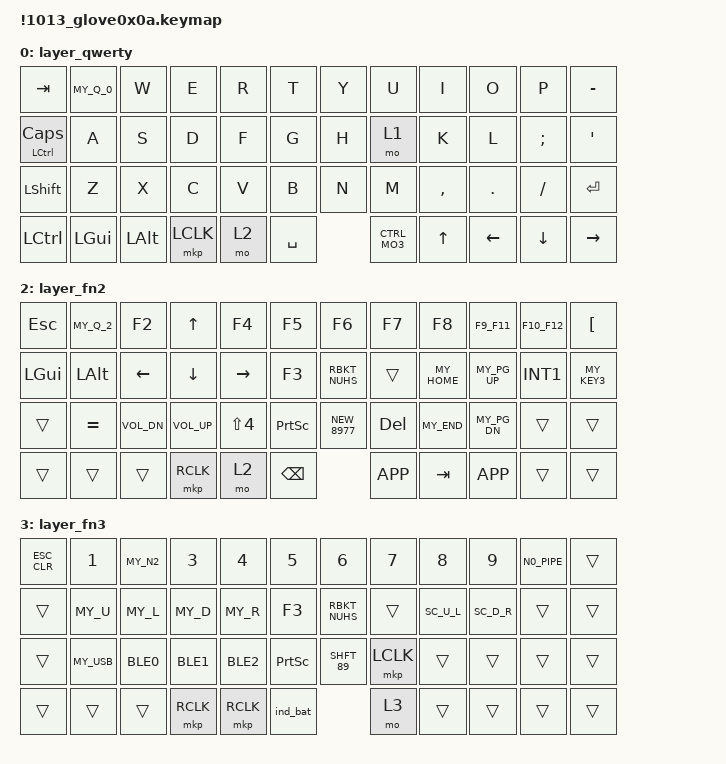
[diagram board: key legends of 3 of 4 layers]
#include <behaviors.dtsi>
#include <dt-bindings/zmk/keys.h>
#include <dt-bindings/zmk/bt.h>
#include <dt-bindings/zmk/outputs.h>
#include <dt-bindings/zmk/rgb.h>
#include <behaviors/rgbled_widget.dtsi>

//define
//ロータリーエンコーダ：マウスのスクロール量
#define ZMK_POINTING_DEFAULT_MOVE_VAL 1500
#define ZMK_POINTING_DEFAULT_SCRL_VAL 60
#include <dt-bindings/zmk/pointing.h>
#include <dt-bindings/input/input-event-codes.h>

#define TAP_MS 200
#define HOLD_MS 200
#define PIPE_ LS(INT3)

#define _USB OUT_USB
#define _BLE OUT_BLE
#define _BT  BT_SEL

#define SC_U SCRL_UP
#define SC_D SCRL_DOWN
#define SC_L SCRL_LEFT
#define SC_R SCRL_RIGHT

#define DUMM MOVE_Y(-1)
#define LO_U MOVE_Y(-1000)
#define LO_D MOVE_Y(1000)
#define LO_L MOVE_X(-1000)
#define LO_R MOVE_X(1000)
#define HI_U MOVE_Y(-200)
#define HI_D MOVE_Y(200)
#define HI_L MOVE_X(-200)
#define HI_R MOVE_X(200)

//2026.03.17 #980 Ctrl + TAB or Q(Shift TAB) / Alt + Q(TAB) or W(Shit+TAB)
//2026.03.16 #979 Layer1のGUI押下中のHOME/END/PGUP/PGDNをLC()送付&GUIリリース前にESC送信に修正(mod-morph)。
//2026.03.16 #968 没。めっちゃムズイ。バッテリー監視も無効になる。:WS2812(LED)の有効化/AZ1UBALLから並列で電源供給
//2026.03.14 #921 ダブルタップは250ms(ちょっと余裕がある)
//2026.03.14 #919 Q、TABへ。mod-morphの修飾キーマスク削除。
//2026.03.14 #919 hold-tapで他キー割込み時はhold->tap扱いへ
//2026.03.14 #907 fn2度押し->Ctrlへ。
//2026.03.13 #881 tap-danceの自動リリース削除、押しっぱなしでホールド/即リリースは後追い。
//2026.03.12 #873 物理配置を再調整。D1が不調。
//2026.03.03 #860   レイヤー3で左クリック
//2026.03.02 #853 i2c/jiggler/加速度/47キー/マウス基本を低速へ//2026.03.02 #852   47キーバージョンへ戻し。左下キー削減のリハビリから。
//2026.03.01 #847   Ctrlキーを再配置、BLE機能関連のキー再配置
//2026.03.01 #843 デバッグ:AZ1UBALL:加速度上限制御。//2026.03.01 #842 デバッグ:AZ1UBALL:前回移動量のクリアを明記。//2026.03.01 #841 デバッグ:AZ1UBALL:前回移動量の保存条件を変更。//2026.03.01 #838 デバッグ:AZ1UBALL:cos/sinの符号不良。//2026.03.01 #837 デバッグ:AZ1UBALL:方向検出不良(if右else左else下else上->if右else左 if下else上)//2026.02.28 #834 デバッグ:AZ1UBALL:加速度不良。
//2026.02.28 #832 左Fnのレイヤー上段にFXを集約。整理。
//2026.02.28 #828 AZ1UBALLのカスタマイズ。移動量,角度,加速度。
//2026.02.23 #800 I2Cでマウス、ジグラーはレイヤー1へ。Fn2で速度追加、Fn3でカーソル。レイヤー1は未点灯。
//2026.02.23 #798 I2Cでマウス、Fn1で速度追加、Fn2でカーソル、ジグラーはレイヤー3へ。
//2026.02.23 #765 I2CのSDA(D4)、SCL(D5)を明示的に指定。
//2026.02.23 #764 zmkバージョンアップにより、rgbledをローカルzmkへ統合。OK
//2026.02.23 #764 ZIGGLER ON/OFFのため、JキーをF13へ。(物理スイッチあり)
&mt {
    tapping-term-ms = <HOLD_MS>;  //hold-tap / caps -> Ctrl
};
/ {
//★macro---------------------------------------------------
    macros {
        MY_USB: MY_USB {
            compatible = "zmk,behavior-macro";
            #binding-cells = <0>;
            bindings
                = <&macro_tap &out OUT_USB>
                , <&macro_tap &bt BT_SEL 5 >;
        };
        BLE0: BLE0 {
            compatible = "zmk,behavior-macro";
            #binding-cells = <0>;
            bindings
                = <&macro_tap &out OUT_BLE>
                , <&macro_tap &bt BT_SEL 0 >;
        };
        BLE1: BLE1 {
            compatible = "zmk,behavior-macro";
            #binding-cells = <0>;
            bindings
                = <&macro_tap &out OUT_BLE>
                , <&macro_tap &bt BT_SEL 1 >;
        };
        BLE2: BLE2 {
            compatible = "zmk,behavior-macro";
            #binding-cells = <0>;
            bindings
                = <&macro_tap &out OUT_BLE>
                , <&macro_tap &bt BT_SEL 2 >;
        };
        N_RBKT_NUHS: N_RBKT_NUHS {
            compatible = "zmk,behavior-macro";
            #binding-cells = <0>;
            bindings
                = <&kp RBKT &kp NUHS &kp LEFT>;
        };
        S_RBKT_NUHS: S_RBKT_NUHS {
            compatible = "zmk,behavior-macro";
            #binding-cells = <0>;
            bindings
                = <&kp LS(RBKT) &kp LS(NUHS) &kp LEFT>;
        };
        SHFT_89: SHFT_89 {
            compatible = "zmk,behavior-macro";
            #binding-cells = <0>;
            bindings
                = <&kp LS(N8) &kp LS(N9) &kp LEFT>;
        };
        SHFT_77: SHFT_77 {
            compatible = "zmk,behavior-macro";
            #binding-cells = <0>;
            bindings
                = <&kp LS(N7) &kp LS(N7) &kp LEFT>;
        };
        SHFT_22: SHFT_22 {
            compatible = "zmk,behavior-macro";
            #binding-cells = <0>;
            bindings
                = <&kp LS(N2) &kp LS(N2) &kp LEFT>;
        };
    };
////behaviors
    behaviors {
//★mod-morph-----------------------------------------------
        //ボリューム操作(Win->UNIX)
        VOL_UP: VOL_UP {
            compatible = "zmk,behavior-mod-morph";
            #binding-cells = <0>;
            bindings = <&kp C_VOL_UP>, <&kp K_VOL_UP>;
            mods = <MOD_LSFT>;
        };
        VOL_DN: VOL_DN {
            compatible = "zmk,behavior-mod-morph";
            #binding-cells = <0>;
            bindings = <&kp C_VOL_DN>, <&kp K_VOL_DN>;
            mods = <MOD_LSFT>;
        };
        //0.ESC
        ESC_CLR: ESC_CLR {  /*ESC_CLR*/
            compatible = "zmk,behavior-mod-morph";
            #binding-cells = <0>;
            bindings = <&kp ESC>, <&bt BT_CLR >;
            mods = <MOD_LSFT>;
        };
        //1.Q
        MY_Q_0: MY_Q_0 {  //Alt or Ctrl
            compatible = "zmk,behavior-mod-morph";
            #binding-cells = <0>;
            bindings = <&kp Q>, <&kp LS(TAB)>;
            mods = <(MOD_LALT|MOD_LCTL)>;
        };
        QUIT_F1: QUIT_F1 {  /* QUIT_F1 */
            compatible = "zmk,behavior-mod-morph";
            #binding-cells = <0>;
            bindings = <&kp LA(F4)>, <&kp F1>;
            mods = <MOD_LSFT>;
        };
        MY_Q_2: MY_Q_2 {    //Alt
            compatible = "zmk,behavior-mod-morph";
            #binding-cells = <0>;
            bindings = <&QUIT_F1>, <&kp TAB >;
            mods = <(MOD_LALT|MOD_LCTL)>;
        };
        //9.O
        F9_F11: F9_F11 {    /* F9_F11 */
            compatible = "zmk,behavior-mod-morph";
            #binding-cells = <0>;
            bindings = <&kp F9>, <&kp F11>;
            mods = <MOD_LSFT>;
        };
        //10.P
        F10_F12: F10_F12 {  /* F10_F12 */
            compatible = "zmk,behavior-mod-morph";
            #binding-cells = <0>;
            bindings = <&kp F10>, <&kp F12>;
            mods = <MOD_LSFT>;
        };
        N0_PIPE: N0_PIPE {  /* N0 & pipe */
            compatible = "zmk,behavior-mod-morph";
            #binding-cells = <0>;
            bindings = <&kp N0>, <&kp PIPE_>;
            mods = <MOD_LSFT>;
        };
        //23.:
        MY_KEY3: MY_KEY3 {  /*【~】【*】 */
            compatible = "zmk,behavior-mod-morph";
            #binding-cells = <0>;
            bindings = <&kp LS(EQUAL)>, <&kp LS(SQT)>;
            mods = <MOD_LSFT>;
        };
        //NEW_2:
        MY_N2: MY_N2 {
            compatible = "zmk,behavior-mod-morph";
            #binding-cells = <0>;
            bindings = <&kp N2>, <&SHFT_22>;
            mods = <MOD_LSFT>;
        };
        //NEW_8977:
        RBKT_NUHS: RBKT_NUHS {
            compatible = "zmk,behavior-mod-morph";
            #binding-cells = <0>;
            bindings = <&N_RBKT_NUHS>, <&S_RBKT_NUHS>;
            mods = <MOD_LSFT>;
        };
        //NEW_8977:
        NEW_8977: NEW_8977 {
            compatible = "zmk,behavior-mod-morph";
            #binding-cells = <0>;
            bindings = <&SHFT_89>, <&SHFT_77>;
            mods = <MOD_LSFT>;
        };
//////////十字キー
        MY_R: MY_R{
            compatible = "zmk,behavior-mod-morph";
            #binding-cells = <0>;
            bindings = <&mmv LO_R>, <&mmv HI_R>;
            mods = <MOD_LSFT>;
        };
        MY_U: MY_U{
            compatible = "zmk,behavior-mod-morph";
            #binding-cells = <0>;
            bindings = <&mmv LO_U>, <&mmv HI_U>;
            mods = <MOD_LSFT>;
        };
        MY_L: MY_L{
            compatible = "zmk,behavior-mod-morph";
            #binding-cells = <0>;
            bindings = <&mmv LO_L>, <&mmv HI_L>;
            mods = <MOD_LSFT>;
        };
        MY_D: MY_D{
            compatible = "zmk,behavior-mod-morph";
            #binding-cells = <0>;
            bindings = <&mmv LO_D>, <&mmv HI_D>;
            mods = <MOD_LSFT>;
        };
//////////スクロール
        SC_U_L: SC_U_L{
            compatible = "zmk,behavior-mod-morph";
            #binding-cells = <0>;
            bindings = <&msc SC_U>, <&msc SC_L>;
            mods = <MOD_LSFT>;
        };
        SC_D_R: SC_D_R{
            compatible = "zmk,behavior-mod-morph";
            #binding-cells = <0>;
            bindings = <&msc SC_D>, <&msc SC_R>;
            mods = <MOD_LSFT>;
        };
//////////ページ操作
        MY_HOME: MY_HOME {
            compatible = "zmk,behavior-mod-morph";
            #binding-cells = <0>;
            bindings = <&kp HOME>, <&kp LC(HOME) >;
            mods = <MOD_LGUI>;
        };
        MY_END: MY_END {
            compatible = "zmk,behavior-mod-morph";
            #binding-cells = <0>;
            bindings = <&kp END>, <&kp LC(END) >;
            mods = <MOD_LGUI>;
        };
        MY_PG_UP: MY_PG_UP {
            compatible = "zmk,behavior-mod-morph";
            #binding-cells = <0>;
            bindings = <&kp PG_UP>, <&kp LC(PG_UP) >;
            mods = <MOD_LGUI>;
        };
        MY_PG_DN: MY_PG_DN {
            compatible = "zmk,behavior-mod-morph";
            #binding-cells = <0>;
            bindings = <&kp PG_DN>, <&kp LC(PG_DN) >;
            mods = <MOD_LGUI>;
        };
//★LED制御-------------------------------------------------
        capslock_led: capslock_led {
            compatible = "zmk,behavior-status-indicator";
            #binding-cells = <0>;
            behavior-status = "capslock";
            outputs = <&caps_led>;  // ✅ ラベルと一致
        };
//★タップダンス制御-------------------------------------------------
        CTRL_MO3: CTRL_MO3 {
            compatible = "zmk,behavior-tap-dance";
            #binding-cells = <0>;
            tapping-term-ms = <TAP_MS>;
            bindings = <
                &mo 3
                &kp LCTRL
            >;
        };
    };
    //aliases
    aliases {
        led-red = &caps_led;     // ✅ DT_ALIAS(led_red) が &caps_led を参照
        led-green = &led1;
        led-blue = &led2;
    };
    //leds
    leds {
        compatible = "gpio-leds";
        status = "okay";

        caps_led: caps_led {
            gpios = <&gpio0 26 GPIO_ACTIVE_LOW>;  // ✅ P0.26 に接続された赤LED
            label = "CapsLock LED";               // ✅ GPIO識別用ラベル
        };

        led1: led_1 {
            gpios = <&gpio0 30 GPIO_ACTIVE_LOW>;
            label = "Green LED";
        };

        led2: led_2 {
            gpios = <&gpio0 6 GPIO_ACTIVE_LOW>;
            label = "Blue LED";
        };
    };

    //keymap
    keymap {
        compatible = "zmk,keymap";
        //0:normal
//|----|*****|----|*****|----|*****|----|*****|----|*****|----|*****|----|*****|----|*****|----|*****|----|*****|----|*****|----|*****
        layer_qwerty {
          bindings = <
  &kp  TAB   &MY_Q_0    &kp  W     &kp  E     &kp  R     &kp  T     &kp  Y     &kp  U     &kp  I     &kp  O     &kp  P     &kp  MINUS
  &mt  LCTRL CAPS &kp A &kp  S     &kp  D     &kp  F     &kp  G     &kp  H     &mo  1     &kp  K     &kp  L     &kp  SEMI  &kp  SQT
  &kp  LSHFT &kp Z      &kp  X     &kp  C     &kp  V     &kp  B     &kp  N     &kp  M     &kp  COMMA &kp  DOT   &kp  SLASH &kp  ENTER
  &kp  LCTRL &kp LGUI   &kp  LALT  &mkp LCLK  &mo 2      &kp  SPACE            &CTRL_MO3  &kp  UP    &kp  LEFT  &kp  DOWN  &kp  RIGHT
          >;
        };
        //1:jigler-dummyレイヤー
        layer_fn1 { bindings = < &trans &trans &trans &trans &trans &trans &trans &trans &trans &trans &trans &trans &trans &trans &trans &trans &trans &trans &trans &trans &trans &trans &trans &trans &trans &trans &trans &trans &trans &trans &trans &trans &trans &trans &trans &trans &trans &trans &trans &trans &trans &trans &trans &trans &trans &trans &trans &trans >; };
        //2:Custom + Function Keys + Vol
        layer_fn2 {
          bindings = <
  &kp  ESC   &MY_Q_2    &kp F2     &kp  UP    &kp  F4    &kp  F5    &kp  F6    &kp  F7    &kp  F8    &F9_F11    &F10_F12   &kp  LBKT
  &kp  LGUI  &kp LALT   &kp  LEFT  &kp  DOWN  &kp  RIGHT &kp  F3    &RBKT_NUHS &trans     &MY_HOME   &MY_PG_UP  &kp  INT1  &MY_KEY3
  &trans     &kp EQUAL  &VOL_DN    &VOL_UP    &kp LS(N4) &kp  PSCRN &NEW_8977  &kp  DEL   &MY_END    &MY_PG_DN  &trans     &trans
  &trans     &trans     &trans     &mkp RCLK  &mo  2     &kp  BSPC             &kp  K_APP &kp  TAB   &kp  K_APP &trans     &trans
          >;
        };
        //3:Number + Bluetooth /マウス高速
        layer_fn3 {
          bindings = <
  &ESC_CLR   &kp  N1    &MY_N2     &kp  N3    &kp N4     &kp  N5    &kp  N6    &kp  N7    &kp  N8    &kp  N9    &N0_PIPE   &trans
  &trans     &MY_U      &MY_L      &MY_D      &MY_R      &kp  F3    &RBKT_NUHS &trans     &SC_U_L    &SC_D_R    &trans     &trans
  &trans     &MY_USB    &BLE0      &BLE1      &BLE2      &kp  PSCRN &SHFT_89   &mkp LCLK  &trans     &trans     &trans     &trans
  &trans     &trans     &trans     &mkp RCLK  &mkp RCLK  &ind_bat              &mo  3     &trans     &trans     &trans     &trans
          >;
        };
    };
};

//&ind_bat
//        _vol_mute: _vol_mute {
//            compatible = "zmk,behavior-mod-morph";
//            #binding-cells = <0>;
//            bindings = <&kp C_MUTE>, <&kp K_MUTE>;
//            mods = <MOD_LSFT>;
//        };
//        MY_KEY4: MY_KEY4 {  /*【^】【(】*/
//            compatible = "zmk,behavior-mod-morph";
//            #binding-cells = <0>;
//            bindings = <&kp EQUAL>, <&kp LS(N8)>;
//            mods = <MOD_LSFT>;
//        };
//        MY_KEY5: MY_KEY5 {  /*【$】【)】*/
//            compatible = "zmk,behavior-mod-morph";
//            #binding-cells = <0>;
//            bindings = <&kp LS(N4)>, <&kp LS(N9)>;
//            mods = <MOD_LSFT>;
//        };
//        USB_BLE: USB_BLE {  /*USB or BLE*/
//            compatible = "zmk,behavior-mod-morph";
//            #binding-cells = <0>;
//            bindings = <&out _USB>, <&out _BLE>;
//            mods = <MOD_LSFT>;
//        };
//        //MY_A_0: MY_A_0 {
        //    compatible = "zmk,behavior-mod-morph";
        //    #binding-cells = <0>;
        //    bindings = <&mt LSHFT A>, <&mt LSHFT A>;
        //    mods = <MOD_LCTL>;
        //};
        //MY_A_2: MY_A_2 {
        //    compatible = "zmk,behavior-mod-morph";
        //    #binding-cells = <0>;
        //    bindings = <&kp LALT>, <&kp LSHFT>;
        //    mods = <MOD_LCTL>;
        //};
        //MY_SPAC_w0: MY_SPAC_w0 {
        //    compatible = "zmk,behavior-mod-morph";
        //    #binding-cells = <0>;
        //    bindings = <&kp SPACE>, <&kp LS(A)>;
        //    mods = <MOD_LSFT>;
        //};
        //MY_SPAC_0: MY_SPAC_0 {
        //    compatible = "zmk,behavior-mod-morph";
        //    #binding-cells = <0>;
        //    bindings = <&MY_SPAC_w0>, <&kp LC(Z)>;
        //    mods = <MOD_LCTL>;
        //};
//★モッドタップ-------------------------------------------------
        //mZ: mZ {
        //    compatible = "zmk,behavior-hold-tap";
        //    #binding-cells = <2>;
        //    flavor = "hold-preferred";
        //    tapping-term-ms = <100>;
        //    bindings = <&kp>, <&MY_KEY4>;
        //    display-name = "Mod-Tap";
        //};
        //Shift以外は、修飾キーマスクなし。MOD_LCTL
        //MY_Z_0: MY_Z_0 {  //Ctrl+Zの長押しに対応するため、Ctrl押下済みならZのまま。未押下状態なら
        //    compatible = "zmk,behavior-mod-morph";
        //    #binding-cells = <0>;
        //    bindings = <&mt LCTRL Z >, <&kp Z>;
        //    mods = <MOD_LCTL>;
        //};
//        CTRL_MO2: CTRL_MO2 {
//            compatible = "zmk,behavior-tap-dance";
//            #binding-cells = <0>;
//            tapping-term-ms = <TAP_MS>;
//            bindings = <
//                &mo 2
//                &kp LCTRL
//            >;
//        };
//        //25.Z
//      MY_KEY4: MY_KEY4 {  /*【^】【$】 */
//          compatible = "zmk,behavior-mod-morph";
//          #binding-cells = <0>;
//          bindings = <&kp EQUAL>, <&kp LS(N4)>;
//          mods = <MOD_LSFT>;
//      };
        //2.W
        //MY_W_0: MY_W_0 {     //Alt
        //    compatible = "zmk,behavior-mod-morph";
        //    #binding-cells = <0>;
        //    bindings = <&kp W>, <&kp LS(TAB)>;
        //    mods = <MOD_LALT>;
        //};
        //MY_W_2: MY_W_2 {     //Alt
        //    compatible = "zmk,behavior-mod-morph";
        //    #binding-cells = <0>;
        //    bindings = <&kp F2>, <&kp LS(TAB)>;
        //    mods = <MOD_LALT>;
        //};
        //18.H
        //MY_KEY1: MY_KEY1 {  /* 【'】【"】*/
        //    compatible = "zmk,behavior-mod-morph";
        //    #binding-cells = <0>;
        //    bindings = <&kp LS(N7)>, <&kp LS(N2)>;
        //    mods = <MOD_LSFT>;
        //};
        //30.N
        //MY_KEY2: MY_KEY2 {  /*【&】【|】*/
        //    compatible = "zmk,behavior-mod-morph";
        //    #binding-cells = <0>;
        //    bindings = <&kp LS(N6)>, <&kp PIPE_>;
        //    mods = <MOD_LSFT>;
        //};
        ////18.H
        //TD_RBKT: TD_RBKT {
        //    compatible = "zmk,behavior-tap-dance";
        //    #binding-cells = <0>;
        //    tapping-term-ms = <TAP_MS>;
        //    bindings = <
        //        &kp RBKT
        //        &kp LS(N8)
        //    >;
        //};
        ////30.N
        //TD_NUHS: TD_NUHS {
        //    compatible = "zmk,behavior-tap-dance";
        //    #binding-cells = <0>;
        //    tapping-term-ms = <TAP_MS>;
        //    bindings = <
        //        &kp NUHS
        //        &kp LS(N9)
        //    >;
        //};
        //holdR: holdR {
        //    compatible = "zmk,behavior-hold-tap";
        //    #binding-cells = <2>;
        //    flavor = "hold-preferred";
        //    tapping-term-ms = <HOLD_MS>;
        //    bindings = <&MY_R>, <&kp>;
        //    display-name = "Mod-Tap";
        //};
        //holdU: holdU {
        //    compatible = "zmk,behavior-hold-tap";
        //    #binding-cells = <2>;
        //    flavor = "hold-preferred";
        //    tapping-term-ms = <HOLD_MS>;
        //    bindings = <&MY_U>, <&kp>;
        //    display-name = "Mod-Tap";
        //};
        //holdL: holdL {
        //    compatible = "zmk,behavior-hold-tap";
        //    #binding-cells = <2>;
        //    flavor = "hold-preferred";
        //    tapping-term-ms = <HOLD_MS>;
        //    bindings = <&MY_L>, <&kp>;
        //    display-name = "Mod-Tap";
        //};
        //holdD: holdD {
        //    compatible = "zmk,behavior-hold-tap";
        //    #binding-cells = <2>;
        //    flavor = "hold-preferred";
        //    tapping-term-ms = <HOLD_MS>;
        //    bindings = <&MY_D>, <&kp>;
        //    display-name = "Mod-Tap";
        //};
